# STM32F7x6 register map
File version: 1.3
CPU: CM7 r0p0, little endian, no MPU, no FPU, 3 interrupt priority bits
Registers are 32-bit, read-write, reset 0x0 unless marked. A register's access mark holds for its fields unless they carry their own. Offsets are from the block's base; [hi:lo] are bit positions.

## SPDIF_RX — Receiver Interface
Base 0x40004000
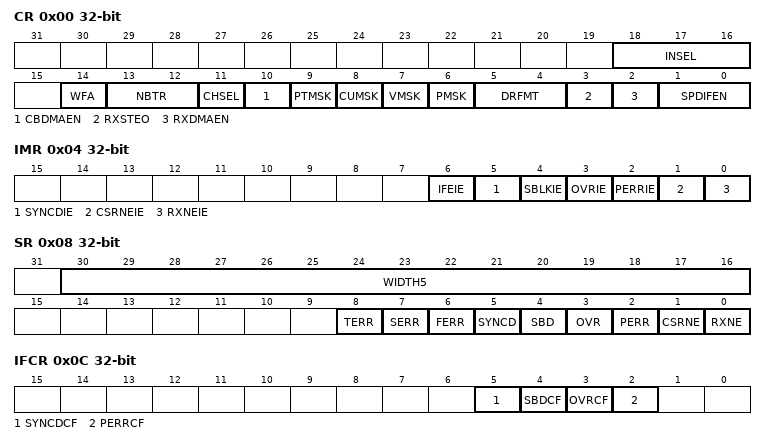
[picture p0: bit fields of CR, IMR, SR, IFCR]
0x00 CR — Control register
  [18:16] INSEL — input selection
  [14] WFA — Wait For Activity
  [13:12] NBTR — Maximum allowed re-tries during synchronization phase
  [11] CHSEL — Channel Selection
  [10] CBDMAEN — Control Buffer DMA ENable for control flow
  [9] PTMSK — Mask of Preamble Type bits
  [8] CUMSK — Mask of channel status and user bits
  [7] VMSK — Mask of Validity bit
  [6] PMSK — Mask Parity error bit
  [5:4] DRFMT — RX Data format
  [3] RXSTEO — STerEO Mode
  [2] RXDMAEN — Receiver DMA ENable for data flow
  [1:0] SPDIFEN — Peripheral Block Enable
0x04 IMR — Interrupt mask register
  [6] IFEIE — Serial Interface Error Interrupt Enable
  [5] SYNCDIE — Synchronization Done
  [4] SBLKIE — Synchronization Block Detected Interrupt Enable
  [3] OVRIE — Overrun error Interrupt Enable
  [2] PERRIE — Parity error interrupt enable
  [1] CSRNEIE — Control Buffer Ready Interrupt Enable
  [0] RXNEIE — RXNE interrupt enable
0x08 SR ro — Status register
  [30:16] WIDTH5 — Duration of 5 symbols counted with SPDIF_CLK
  [8] TERR — Time-out error
  [7] SERR — Synchronization error
  [6] FERR — Framing error
  [5] SYNCD — Synchronization Done
  [4] SBD — Synchronization Block Detected
  [3] OVR — Overrun error
  [2] PERR — Parity error
  [1] CSRNE — Control Buffer register is not empty
  [0] RXNE — Read data register not empty
0x0C IFCR wo — Interrupt Flag Clear register
  [5] SYNCDCF — Clears the Synchronization Done flag
  [4] SBDCF — Clears the Synchronization Block Detected flag
  [3] OVRCF — Clears the Overrun error flag
  [2] PERRCF — Clears the Parity error flag
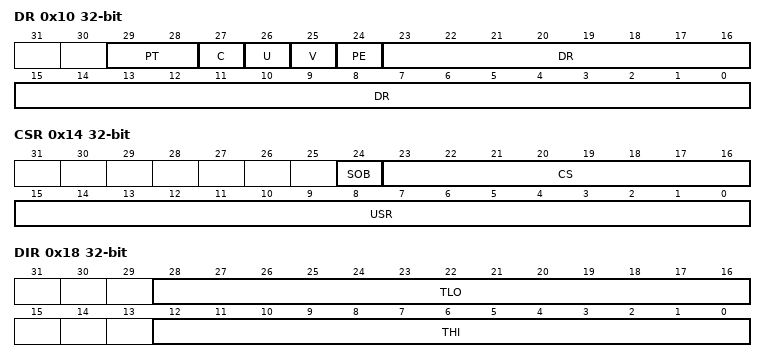
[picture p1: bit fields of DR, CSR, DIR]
0x10 DR ro — Data input register
  [29:28] PT — Preamble Type
  [27] C — Channel Status bit
  [26] U — User bit
  [25] V — Validity bit
  [24] PE — Parity Error bit
  [23:0] DR — Parity Error bit
0x14 CSR ro — Channel Status register
  [24] SOB — Start Of Block
  [23:16] CS — Channel A status information
  [15:0] USR — User data information
0x18 DIR ro — Debug Information register
  [28:16] TLO — Threshold LOW
  [12:0] THI — Threshold HIGH

## LPTIM1 — Low power timer
Base 0x40002400
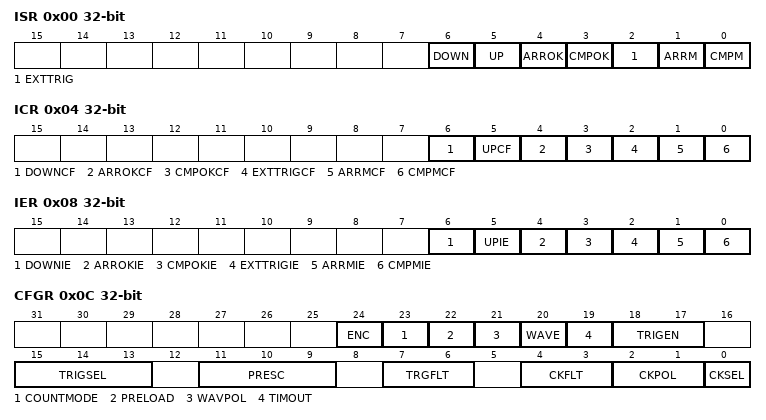
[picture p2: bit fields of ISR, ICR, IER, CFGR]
0x00 ISR ro — Interrupt and Status Register
  [6] DOWN — Counter direction change up to down
  [5] UP — Counter direction change down to up
  [4] ARROK — Autoreload register update OK
  [3] CMPOK — Compare register update OK
  [2] EXTTRIG — External trigger edge event
  [1] ARRM — Autoreload match
  [0] CMPM — Compare match
0x04 ICR wo — Interrupt Clear Register
  [6] DOWNCF — Direction change to down Clear Flag
  [5] UPCF — Direction change to UP Clear Flag
  [4] ARROKCF — Autoreload register update OK Clear Flag
  [3] CMPOKCF — Compare register update OK Clear Flag
  [2] EXTTRIGCF — External trigger valid edge Clear Flag
  [1] ARRMCF — Autoreload match Clear Flag
  [0] CMPMCF — compare match Clear Flag
0x08 IER — Interrupt Enable Register
  [6] DOWNIE — Direction change to down Interrupt Enable
  [5] UPIE — Direction change to UP Interrupt Enable
  [4] ARROKIE — Autoreload register update OK Interrupt Enable
  [3] CMPOKIE — Compare register update OK Interrupt Enable
  [2] EXTTRIGIE — External trigger valid edge Interrupt Enable
  [1] ARRMIE — Autoreload match Interrupt Enable
  [0] CMPMIE — Compare match Interrupt Enable
0x0C CFGR — Configuration Register
  [24] ENC — Encoder mode enable
  [23] COUNTMODE — counter mode enabled
  [22] PRELOAD — Registers update mode
  [21] WAVPOL — Waveform shape polarity
  [20] WAVE — Waveform shape
  [19] TIMOUT — Timeout enable
  [18:17] TRIGEN — Trigger enable and polarity
  [15:13] TRIGSEL — Trigger selector
  [11:9] PRESC — Clock prescaler
  [7:6] TRGFLT — Configurable digital filter for trigger
  [4:3] CKFLT — Configurable digital filter for external clock
  [2:1] CKPOL — Clock Polarity
  [0] CKSEL — Clock selector
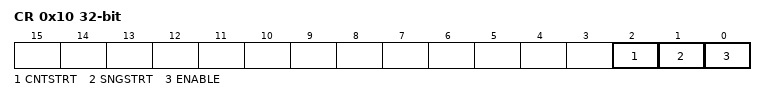
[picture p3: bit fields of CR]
0x10 CR — Control Register
  [2] CNTSTRT — Timer start in continuous mode
  [1] SNGSTRT — LPTIM start in single mode
  [0] ENABLE — LPTIM Enable
0x14 CMP — Compare Register
  [15:0] CMP — Compare value
0x18 ARR reset 0x1 — Autoreload Register
  [15:0] ARR — Auto reload value
0x1C CNT ro — Counter Register
  [15:0] CNT — Counter value
